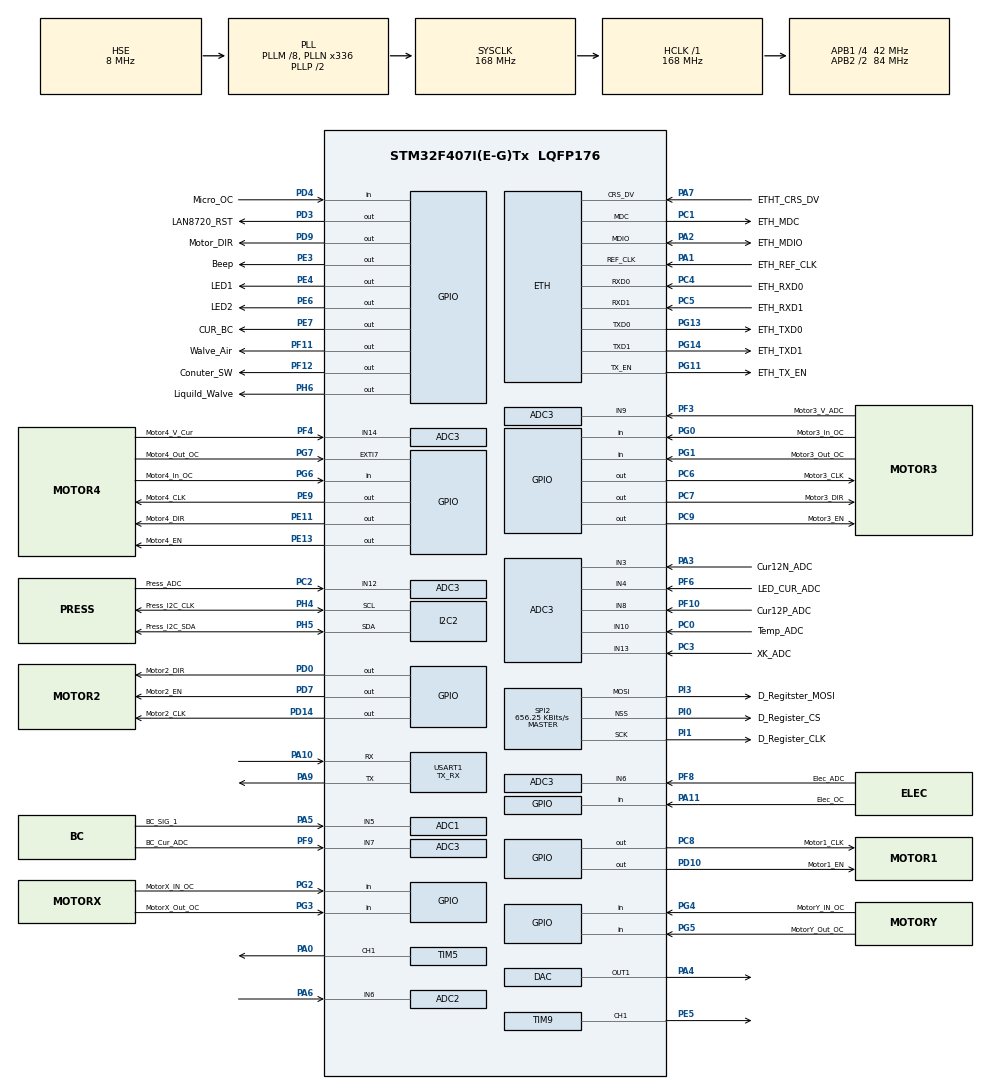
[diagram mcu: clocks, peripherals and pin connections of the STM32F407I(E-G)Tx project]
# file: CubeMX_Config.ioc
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ADC1.Channel-0\#ChannelRegularConversion=ADC_CHANNEL_5
ADC1.ContinuousConvMode=ENABLE
ADC1.DMAContinuousRequests=ENABLE
ADC1.InjNumberOfConversion=0
ADC1.NbrOfConversion=1
ADC1.NbrOfConversionFlag=1
ADC1.Rank-0\#ChannelRegularConversion=1
ADC1.SamplingTime-0\#ChannelRegularConversion=ADC_SAMPLETIME_3CYCLES
ADC1.master=1
ADC2.Channel-0\#ChannelRegularConversion=ADC_CHANNEL_6
ADC2.ContinuousConvMode=ENABLE
ADC2.DMAContinuousRequests=ENABLE
ADC2.NbrOfConversionFlag=1
ADC2.Rank-0\#ChannelRegularConversion=1
ADC2.SamplingTime-0\#ChannelRegularConversion=ADC_SAMPLETIME_3CYCLES
ADC2.ScanConvMode=ENABLE
ADC3.Channel-0\#ChannelRegularConversion=ADC_CHANNEL_13
ADC3.Channel-1\#ChannelRegularConversion=ADC_CHANNEL_7
ADC3.Channel-2\#ChannelRegularConversion=ADC_CHANNEL_6
ADC3.Channel-3\#ChannelRegularConversion=ADC_CHANNEL_3
ADC3.Channel-4\#ChannelRegularConversion=ADC_CHANNEL_8
ADC3.Channel-5\#ChannelRegularConversion=ADC_CHANNEL_9
ADC3.Channel-6\#ChannelRegularConversion=ADC_CHANNEL_14
ADC3.Channel-7\#ChannelRegularConversion=ADC_CHANNEL_12
ADC3.Channel-8\#ChannelRegularConversion=ADC_CHANNEL_4
ADC3.Channel-9\#ChannelRegularConversion=ADC_CHANNEL_10
ADC3.ContinuousConvMode=ENABLE
ADC3.NbrOfConversion=10
ADC3.NbrOfConversionFlag=1
ADC3.Rank-0\#ChannelRegularConversion=1
ADC3.Rank-1\#ChannelRegularConversion=2
ADC3.Rank-2\#ChannelRegularConversion=3
ADC3.Rank-3\#ChannelRegularConversion=4
ADC3.Rank-4\#ChannelRegularConversion=5
ADC3.Rank-5\#ChannelRegularConversion=6
ADC3.Rank-6\#ChannelRegularConversion=7
ADC3.Rank-7\#ChannelRegularConversion=8
ADC3.Rank-8\#ChannelRegularConversion=9
ADC3.Rank-9\#ChannelRegularConversion=10
ADC3.SamplingTime-0\#ChannelRegularConversion=ADC_SAMPLETIME_3CYCLES
ADC3.SamplingTime-1\#ChannelRegularConversion=ADC_SAMPLETIME_3CYCLES
ADC3.SamplingTime-2\#ChannelRegularConversion=ADC_SAMPLETIME_3CYCLES
ADC3.SamplingTime-3\#ChannelRegularConversion=ADC_SAMPLETIME_3CYCLES
ADC3.SamplingTime-4\#ChannelRegularConversion=ADC_SAMPLETIME_3CYCLES
ADC3.SamplingTime-5\#ChannelRegularConversion=ADC_SAMPLETIME_3CYCLES
ADC3.SamplingTime-6\#ChannelRegularConversion=ADC_SAMPLETIME_3CYCLES
ADC3.SamplingTime-7\#ChannelRegularConversion=ADC_SAMPLETIME_3CYCLES
ADC3.SamplingTime-8\#ChannelRegularConversion=ADC_SAMPLETIME_3CYCLES
ADC3.SamplingTime-9\#ChannelRegularConversion=ADC_SAMPLETIME_3CYCLES
ADC3.ScanConvMode=ENABLE
DAC.DAC_Trigger=DAC_TRIGGER_NONE
Dma.ADC1.0.Direction=DMA_PERIPH_TO_MEMORY
Dma.ADC1.0.FIFOMode=DMA_FIFOMODE_DISABLE
Dma.ADC1.0.Instance=DMA2_Stream0
Dma.ADC1.0.MemDataAlignment=DMA_MDATAALIGN_HALFWORD
Dma.ADC1.0.MemInc=DMA_MINC_ENABLE
Dma.ADC1.0.Mode=DMA_NORMAL
Dma.ADC1.0.PeriphDataAlignment=DMA_PDATAALIGN_HALFWORD
Dma.ADC1.0.PeriphInc=DMA_PINC_DISABLE
Dma.ADC1.0.Priority=DMA_PRIORITY_HIGH
Dma.ADC2.1.Direction=DMA_PERIPH_TO_MEMORY
Dma.ADC2.1.FIFOMode=DMA_FIFOMODE_DISABLE
Dma.ADC2.1.Instance=DMA2_Stream3
Dma.ADC2.1.MemDataAlignment=DMA_MDATAALIGN_HALFWORD
Dma.ADC2.1.MemInc=DMA_MINC_ENABLE
Dma.ADC2.1.Mode=DMA_NORMAL
Dma.ADC2.1.PeriphDataAlignment=DMA_PDATAALIGN_HALFWORD
Dma.ADC2.1.PeriphInc=DMA_PINC_DISABLE
Dma.ADC2.1.Priority=DMA_PRIORITY_HIGH
Dma.ADC3.2.Direction=DMA_PERIPH_TO_MEMORY
Dma.ADC3.2.FIFOMode=DMA_FIFOMODE_DISABLE
Dma.ADC3.2.Instance=DMA2_Stream1
Dma.ADC3.2.MemDataAlignment=DMA_MDATAALIGN_HALFWORD
Dma.ADC3.2.MemInc=DMA_MINC_ENABLE
Dma.ADC3.2.Mode=DMA_NORMAL
Dma.ADC3.2.PeriphDataAlignment=DMA_PDATAALIGN_HALFWORD
Dma.ADC3.2.PeriphInc=DMA_PINC_DISABLE
Dma.ADC3.2.Priority=DMA_PRIORITY_LOW
Dma.Request0=ADC1
Dma.Request1=ADC2
Dma.Request2=ADC3
ETH.AutoNegotiation=ETH_AUTONEGOTIATION_DISABLE
ETH.MediaInterface=ETH_MEDIA_INTERFACE_RMII
ETH.PHY_Name_RMII=LAN8742A_PHY_ADDRESS
FREERTOS.Tasks01=defaultTask,24,128,StartDefaultTask,Default,NULL,Dynamic,NULL,NULL
LWIP.CHECKSUM_BY_HARDWARE=1
LWIP.GATEWAY_ADDRESS=192.168.001.001
LWIP.IP_ADDRESS=192.168.001.010
LWIP.LWIP_DHCP=0
LWIP.NETMASK_ADDRESS=255.255.255.255
LWIP.Version=v2.1.2_Cube
Mcu.Family=STM32F4
Mcu.Name=STM32F407I(E-G)Tx
Mcu.Package=LQFP176
NVIC.ADC_IRQn=true\:5\:0\:false\:true\:true\:1\:true\:true\:true
NVIC.DMA2_Stream0_IRQn=true\:5\:0\:false\:true\:true\:7\:true\:false\:true
NVIC.DMA2_Stream1_IRQn=true\:5\:0\:false\:true\:true\:8\:true\:false\:true
NVIC.DMA2_Stream3_IRQn=true\:5\:0\:false\:true\:true\:9\:true\:false\:true
NVIC.ETH_IRQn=true\:5\:0\:true\:true\:true\:10\:true\:true\:true
NVIC.EXTI9_5_IRQn=true\:5\:0\:false\:true\:true\:2\:true\:true\:true
NVIC.PriorityGroup=NVIC_PRIORITYGROUP_4
NVIC.TIM1_UP_TIM10_IRQn=true\:5\:0\:false\:true\:true\:3\:true\:false\:true
NVIC.TIM2_IRQn=true\:5\:0\:false\:true\:true\:4\:true\:true\:true
NVIC.TIM8_UP_TIM13_IRQn=true\:5\:0\:false\:true\:true\:6\:true\:true\:true
NVIC.USART1_IRQn=true\:5\:0\:false\:true\:true\:5\:true\:true\:true
PA0-WKUP.Signal=S_TIM5_CH1
PA1.GPIO_Label=ETH_REF_CLK
PA1.Mode=RMII
PA1.Signal=ETH_REF_CLK
PA10.Mode=Asynchronous
PA10.Signal=USART1_RX
PA11.GPIO_Label=Elec_OC
PA11.Signal=GPIO_Input
PA13.Mode=Serial_Wire
PA13.Signal=SYS_JTMS-SWDIO
PA14.Mode=Serial_Wire
PA14.Signal=SYS_JTCK-SWCLK
PA2.GPIO_Label=ETH_MDIO
PA2.Mode=RMII
PA2.Signal=ETH_MDIO
PA3.GPIO_Label=Cur12N_ADC
PA3.Signal=ADCx_IN3
PA4.Signal=COMP_DAC1_group
PA5.GPIO_Label=BC_SIG_1
PA5.Signal=ADCx_IN5
PA6.Signal=ADCx_IN6
PA7.GPIO_Label=ETHT_CRS_DV
PA7.Mode=RMII
PA7.Signal=ETH_CRS_DV
PA9.Mode=Asynchronous
PA9.Signal=USART1_TX
PC0.GPIO_Label=Temp_ADC
PC0.Signal=ADCx_IN10
PC1.GPIO_Label=ETH_MDC
PC1.Mode=RMII
PC1.Signal=ETH_MDC
PC2.GPIO_Label=Press_ADC
PC2.Signal=ADCx_IN12
PC3.GPIO_Label=XK_ADC
PC3.Signal=ADCx_IN13
PC4.GPIO_Label=ETH_RXD0
PC4.Mode=RMII
PC4.Signal=ETH_RXD0
PC5.GPIO_Label=ETH_RXD1
PC5.Mode=RMII
PC5.Signal=ETH_RXD1
PC6.GPIO_Label=Motor3_CLK
PC6.GPIO_Speed=GPIO_SPEED_FREQ_HIGH
PC6.Signal=GPIO_Output
PC7.GPIO_Label=Motor3_DIR
PC7.Signal=GPIO_Output
PC8.GPIO_Label=Motor1_CLK
PC8.GPIO_Speed=GPIO_SPEED_FREQ_HIGH
PC8.Signal=GPIO_Output
PC9.GPIO_Label=Motor3_EN
PC9.Signal=GPIO_Output
PD0.GPIO_Label=Motor2_DIR
PD0.Signal=GPIO_Output
PD10.GPIO_Label=Motor1_EN
PD10.Signal=GPIO_Output
PD14.GPIO_Label=Motor2_CLK
PD14.GPIO_Speed=GPIO_SPEED_FREQ_HIGH
PD14.Signal=GPIO_Output
PD3.GPIO_Label=LAN8720_RST
PD3.Signal=GPIO_Output
PD4.GPIO_Label=Micro_OC
PD4.Signal=GPIO_Input
PD7.GPIO_Label=Motor2_EN
PD7.Signal=GPIO_Output
PD9.GPIO_Label=Motor_DIR
PD9.Signal=GPIO_Output
PE11.GPIO_Label=Motor4_DIR
PE11.Signal=GPIO_Output
PE13.GPIO_Label=Motor4_EN
PE13.Signal=GPIO_Output
PE3.GPIO_Label=Beep
PE3.Signal=GPIO_Output
PE4.GPIO_Label=LED1
PE4.Signal=GPIO_Output
PE5.Signal=S_TIM9_CH1
PE6.GPIO_Label=LED2
PE6.Signal=GPIO_Output
PE7.GPIO_Label=CUR_BC
PE7.Signal=GPIO_Output
PE9.GPIO_Label=Motor4_CLK
PE9.GPIO_Speed=GPIO_SPEED_FREQ_HIGH
PE9.Signal=GPIO_Output
PF10.GPIO_Label=Cur12P_ADC
PF10.Mode=IN8
PF10.Signal=ADC3_IN8
PF11.GPIO_Label=Walve_Air
PF11.Signal=GPIO_Output
PF12.GPIO_Label=Conuter_SW
PF12.Signal=GPIO_Output
PF3.GPIO_Label=Motor3_V_ADC
PF3.Mode=IN9
PF3.Signal=ADC3_IN9
PF4.GPIO_Label=Motor4_V_Cur
PF4.Mode=IN14
PF4.Signal=ADC3_IN14
PF6.GPIO_Label=LED_CUR_ADC
PF6.Mode=IN4
PF6.Signal=ADC3_IN4
PF8.GPIO_Label=Elec_ADC
PF8.Mode=IN6
PF8.Signal=ADC3_IN6
PF9.GPIO_Label=BC_Cur_ADC
PF9.Mode=IN7
PF9.Signal=ADC3_IN7
PG0.GPIO_Label=Motor3_In_OC
PG0.Signal=GPIO_Input
PG1.GPIO_Label=Motor3_Out_OC
PG1.Signal=GPIO_Input
PG11.GPIO_Label=ETH_TX_EN
PG11.Mode=RMII
PG11.Signal=ETH_TX_EN
PG13.GPIO_Label=ETH_TXD0
PG13.Mode=RMII
PG13.Signal=ETH_TXD0
PG14.GPIO_Label=ETH_TXD1
PG14.Mode=RMII
PG14.Signal=ETH_TXD1
PG2.GPIO_Label=MotorX_IN_OC
PG2.Signal=GPIO_Input
PG3.GPIO_Label=MotorX_Out_OC
PG3.Signal=GPIO_Input
PG4.GPIO_Label=MotorY_IN_OC
PG4.Signal=GPIO_Input
PG5.GPIO_Label=MotorY_Out_OC
PG5.Signal=GPIO_Input
PG6.GPIO_Label=Motor4_In_OC
PG6.Signal=GPIO_Input
PG7.GPIO_Label=Motor4_Out_OC
PG7.GPIO_ModeDefaultEXTI=GPIO_MODE_IT_RISING
PG7.Signal=GPXTI7
PH0-OSC_IN.Mode=HSE-External-Oscillator
PH0-OSC_IN.Signal=RCC_OSC_IN
PH1-OSC_OUT.Mode=HSE-External-Oscillator
PH1-OSC_OUT.Signal=RCC_OSC_OUT
PH4.GPIO_Label=Press_I2C_CLK
PH4.Mode=I2C
PH4.Signal=I2C2_SCL
PH5.GPIO_Label=Press_I2C_SDA
PH5.Mode=I2C
PH5.Signal=I2C2_SDA
PH6.GPIO_Label=Liquild_Walve
PH6.Signal=GPIO_Output
PI0.GPIO_Label=D_Register_CS
PI0.Mode=NSS_Signal_Hard_Output
PI0.Signal=SPI2_NSS
PI1.GPIO_Label=D_Register_CLK
PI1.Mode=TX_Only_Simplex_Unidirect_Master
PI1.Signal=SPI2_SCK
PI3.GPIO_Label=D_Regitster_MOSI
PI3.Mode=TX_Only_Simplex_Unidirect_Master
PI3.Signal=SPI2_MOSI
ProjectManager.HeapSize=0x200
ProjectManager.StackSize=0x400
ProjectManager.TargetToolchain=MDK-ARM V5
RCC.48MHZClocksFreq_Value=84000000
RCC.AHBFreq_Value=168000000
RCC.APB1CLKDivider=RCC_HCLK_DIV4
RCC.APB1Freq_Value=42000000
RCC.APB1TimFreq_Value=84000000
RCC.APB2CLKDivider=RCC_HCLK_DIV2
RCC.APB2Freq_Value=84000000
RCC.APB2TimFreq_Value=168000000
RCC.CortexFreq_Value=168000000
RCC.HCLKFreq_Value=168000000
RCC.HSE_VALUE=8000000
RCC.HSI_VALUE=16000000
RCC.LSE_VALUE=32768
RCC.PLLM=8
RCC.PLLN=336
RCC.PLLSourceVirtual=RCC_PLLSOURCE_HSE
RCC.SYSCLKFreq_VALUE=168000000
RCC.SYSCLKSource=RCC_SYSCLKSOURCE_PLLCLK
RCC.VCOOutputFreq_Value=336000000
SH.ADCx_IN10.0=ADC3_IN10,IN10
SH.ADCx_IN12.0=ADC3_IN12,IN12
SH.ADCx_IN13.0=ADC3_IN13,IN13
SH.ADCx_IN3.0=ADC3_IN3,IN3
SH.ADCx_IN5.0=ADC1_IN5,IN5
SH.ADCx_IN6.0=ADC2_IN6,IN6
SH.COMP_DAC1_group.0=DAC_OUT1,DAC_OUT1
SH.S_TIM5_CH1.0=TIM5_CH1,PWM Generation1 CH1
SH.S_TIM9_CH1.0=TIM9_CH1,PWM Generation1 CH1
SPI2.BaudRatePrescaler=SPI_BAUDRATEPRESCALER_64
SPI2.CalculateBaudRate=656.25 KBits/s
SPI2.DataSize=SPI_DATASIZE_16BIT
SPI2.Direction=SPI_DIRECTION_2LINES
SPI2.Mode=SPI_MODE_MASTER
SPI2.VirtualNSS=VM_NSSHARD
SPI2.VirtualType=VM_MASTER
TIM1.AutoReloadPreload=TIM_AUTORELOAD_PRELOAD_ENABLE
TIM1.Period=3000-1
TIM1.Prescaler=14-1
TIM2.AutoReloadPreload=TIM_AUTORELOAD_PRELOAD_ENABLE
TIM2.Period=6480-1
TIM2.Prescaler=256-1
TIM5.Channel-PWM\ Generation1\ CH1=TIM_CHANNEL_1
TIM5.OC1Preload_PWM=DISABLE
TIM5.OCPolarity_1=TIM_OCPOLARITY_LOW
TIM5.Prescaler=4199
TIM5.Pulse-PWM\ Generation1\ CH1=10000
TIM8.AutoReloadPreload=TIM_AUTORELOAD_PRELOAD_ENABLE
TIM8.Period=3000-1
TIM8.Prescaler=14-1
TIM9.AutoReloadPreload=TIM_AUTORELOAD_PRELOAD_ENABLE
TIM9.Channel-PWM\ Generation1\ CH1=TIM_CHANNEL_1
TIM9.OC1Preload_PWM=DISABLE
TIM9.OCPolarity_1=TIM_OCPOLARITY_LOW
TIM9.Period=24999
TIM9.Prescaler=83
TIM9.Pulse-PWM\ Generation1\ CH1=0
USART1.Mode=MODE_TX_RX
USART1.OverSampling=UART_OVERSAMPLING_8
USART1.VirtualMode=VM_ASYNC
VP_FREERTOS_VS_CMSIS_V2.Mode=CMSIS_V2
VP_LWIP_VS_Enabled.Mode=Enabled
VP_TIM1_VS_ClockSourceINT.Mode=Internal
VP_TIM2_VS_ClockSourceINT.Mode=Internal
VP_TIM8_VS_ClockSourceINT.Mode=Internal
board=custom

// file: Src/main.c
/* USER CODE BEGIN Header */
/**
  ******************************************************************************
  * @file           : main.c
  * @brief          : Main program body
  ******************************************************************************
  * @attention
  *
  * <h2><center>&copy; Copyright (c) 2020 STMicroelectronics.
  * All rights reserved.</center></h2>
  *
  * This software component is licensed by ST under Ultimate Liberty license
  * SLA0044, the "License"; You may not use this file except in compliance with
  * the License. You may obtain a copy of the License at:
  *                             www.st.com/SLA0044
  *
  ******************************************************************************
  */
/* USER CODE END Header */

#include "main.h"
#include "cmsis_os.h"
#include "lwip.h"

/* USER CODE BEGIN Includes */
#include "NetMsgProcess.h"
/* USER CODE END Includes */

ADC_HandleTypeDef hadc1;
ADC_HandleTypeDef hadc2;
ADC_HandleTypeDef hadc3;
DMA_HandleTypeDef hdma_adc1;
DMA_HandleTypeDef hdma_adc2;
DMA_HandleTypeDef hdma_adc3;

DAC_HandleTypeDef hdac;

I2C_HandleTypeDef hi2c2;

SPI_HandleTypeDef hspi2;

TIM_HandleTypeDef htim1;
TIM_HandleTypeDef htim2;
TIM_HandleTypeDef htim5;
TIM_HandleTypeDef htim8;
TIM_HandleTypeDef htim9;

UART_HandleTypeDef huart1;

/* Definitions for defaultTask */
osThreadId_t defaultTaskHandle;
const osThreadAttr_t defaultTask_attributes = {
  .name = "defaultTask",
  .priority = (osPriority_t) osPriorityNormal,
  .stack_size = 128 * 4
};

void SystemClock_Config(void);
static void MX_GPIO_Init(void);
static void MX_DMA_Init(void);
static void MX_ADC1_Init(void);
static void MX_ADC2_Init(void);
static void MX_ADC3_Init(void);
static void MX_DAC_Init(void);
static void MX_TIM5_Init(void);
static void MX_TIM9_Init(void);
static void MX_USART1_UART_Init(void);
static void MX_I2C2_Init(void);
static void MX_SPI2_Init(void);
static void MX_TIM1_Init(void);
static void MX_TIM2_Init(void);
static void MX_TIM8_Init(void);
void StartDefaultTask(void *argument);

static void MX_NVIC_Init(void);

int main(void)
{

  /* MCU Configuration--------------------------------------------------------*/

  /* Reset of all peripherals, Initializes the Flash interface and the Systick. */
  HAL_Init();

  /* Configure the system clock */
  SystemClock_Config();

  /* Initialize all configured peripherals */
  MX_GPIO_Init();
  MX_DMA_Init();
  MX_ADC1_Init();
  MX_ADC2_Init();
  MX_ADC3_Init();
  MX_DAC_Init();
  MX_TIM5_Init();
  MX_TIM9_Init();
  MX_USART1_UART_Init();
  MX_I2C2_Init();
  MX_SPI2_Init();
  MX_TIM1_Init();
  MX_TIM2_Init();
  MX_TIM8_Init();

  /* Initialize interrupts */
  MX_NVIC_Init();

  /* Init scheduler */
  osKernelInitialize();

  /* Create the thread(s) */
  /* creation of defaultTask */
  defaultTaskHandle = osThreadNew(StartDefaultTask, NULL, &defaultTask_attributes);

  /* Start scheduler */
  osKernelStart();

  /* We should never get here as control is now taken by the scheduler */
  /* Infinite loop */
  while (1)
  {

  }
}

void SystemClock_Config(void)
{
  RCC_OscInitTypeDef RCC_OscInitStruct = {0};
  RCC_ClkInitTypeDef RCC_ClkInitStruct = {0};

  /** Configure the main internal regulator output voltage
  */
  __HAL_RCC_PWR_CLK_ENABLE();
  __HAL_PWR_VOLTAGESCALING_CONFIG(PWR_REGULATOR_VOLTAGE_SCALE1);
  /** Initializes the CPU, AHB and APB busses clocks
  */
  RCC_OscInitStruct.OscillatorType = RCC_OSCILLATORTYPE_HSE;
  RCC_OscInitStruct.HSEState = RCC_HSE_ON;
  RCC_OscInitStruct.PLL.PLLState = RCC_PLL_ON;
  RCC_OscInitStruct.PLL.PLLSource = RCC_PLLSOURCE_HSE;
  RCC_OscInitStruct.PLL.PLLM = 8;
  RCC_OscInitStruct.PLL.PLLN = 336;
  RCC_OscInitStruct.PLL.PLLP = RCC_PLLP_DIV2;
  RCC_OscInitStruct.PLL.PLLQ = 4;
  if (HAL_RCC_OscConfig(&RCC_OscInitStruct) != HAL_OK)
  {
    Error_Handler();
  }
  /** Initializes the CPU, AHB and APB busses clocks
  */
  RCC_ClkInitStruct.ClockType = RCC_CLOCKTYPE_HCLK|RCC_CLOCKTYPE_SYSCLK
                              |RCC_CLOCKTYPE_PCLK1|RCC_CLOCKTYPE_PCLK2;
  RCC_ClkInitStruct.SYSCLKSource = RCC_SYSCLKSOURCE_PLLCLK;
  RCC_ClkInitStruct.AHBCLKDivider = RCC_SYSCLK_DIV1;
  RCC_ClkInitStruct.APB1CLKDivider = RCC_HCLK_DIV4;
  RCC_ClkInitStruct.APB2CLKDivider = RCC_HCLK_DIV2;

  if (HAL_RCC_ClockConfig(&RCC_ClkInitStruct, FLASH_LATENCY_5) != HAL_OK)
  {
    Error_Handler();
  }
}

/**
  * @brief NVIC Configuration.
  * @retval None
  */
static void MX_NVIC_Init(void)
{
  /* ADC_IRQn interrupt configuration */
  HAL_NVIC_SetPriority(ADC_IRQn, 5, 0);
  HAL_NVIC_EnableIRQ(ADC_IRQn);
  /* EXTI9_5_IRQn interrupt configuration */
  HAL_NVIC_SetPriority(EXTI9_5_IRQn, 5, 0);
  HAL_NVIC_EnableIRQ(EXTI9_5_IRQn);
  /* TIM1_UP_TIM10_IRQn interrupt configuration */
  HAL_NVIC_SetPriority(TIM1_UP_TIM10_IRQn, 5, 0);
  HAL_NVIC_EnableIRQ(TIM1_UP_TIM10_IRQn);
  /* TIM2_IRQn interrupt configuration */
  HAL_NVIC_SetPriority(TIM2_IRQn, 5, 0);
  HAL_NVIC_EnableIRQ(TIM2_IRQn);
  /* USART1_IRQn interrupt configuration */
  HAL_NVIC_SetPriority(USART1_IRQn, 5, 0);
  HAL_NVIC_EnableIRQ(USART1_IRQn);
  /* TIM8_UP_TIM13_IRQn interrupt configuration */
  HAL_NVIC_SetPriority(TIM8_UP_TIM13_IRQn, 5, 0);
  HAL_NVIC_EnableIRQ(TIM8_UP_TIM13_IRQn);
  /* DMA2_Stream0_IRQn interrupt configuration */
  HAL_NVIC_SetPriority(DMA2_Stream0_IRQn, 5, 0);
  HAL_NVIC_EnableIRQ(DMA2_Stream0_IRQn);
  /* DMA2_Stream1_IRQn interrupt configuration */
  HAL_NVIC_SetPriority(DMA2_Stream1_IRQn, 5, 0);
  HAL_NVIC_EnableIRQ(DMA2_Stream1_IRQn);
  /* DMA2_Stream3_IRQn interrupt configuration */
  HAL_NVIC_SetPriority(DMA2_Stream3_IRQn, 5, 0);
  HAL_NVIC_EnableIRQ(DMA2_Stream3_IRQn);
  /* ETH_IRQn interrupt configuration */
  HAL_NVIC_SetPriority(ETH_IRQn, 5, 0);
  HAL_NVIC_EnableIRQ(ETH_IRQn);
}

static void MX_ADC1_Init(void)
{

  ADC_ChannelConfTypeDef sConfig = {0};

  /** Configure the global features of the ADC (Clock, Resolution, Data Alignment and number of conversion)
  */
  hadc1.Instance = ADC1;
  hadc1.Init.ClockPrescaler = ADC_CLOCK_SYNC_PCLK_DIV4;
  hadc1.Init.Resolution = ADC_RESOLUTION_12B;
  hadc1.Init.ScanConvMode = DISABLE;
  hadc1.Init.ContinuousConvMode = ENABLE;
  hadc1.Init.DiscontinuousConvMode = DISABLE;
  hadc1.Init.ExternalTrigConvEdge = ADC_EXTERNALTRIGCONVEDGE_NONE;
  hadc1.Init.ExternalTrigConv = ADC_SOFTWARE_START;
  hadc1.Init.DataAlign = ADC_DATAALIGN_RIGHT;
  hadc1.Init.NbrOfConversion = 1;
  hadc1.Init.DMAContinuousRequests = ENABLE;
  hadc1.Init.EOCSelection = ADC_EOC_SINGLE_CONV;
  if (HAL_ADC_Init(&hadc1) != HAL_OK)
  {
    Error_Handler();
  }
  /** Configure for the selected ADC regular channel its corresponding rank in the sequencer and its sample time.
  */
  sConfig.Channel = ADC_CHANNEL_5;
  sConfig.Rank = 1;
  sConfig.SamplingTime = ADC_SAMPLETIME_3CYCLES;
  if (HAL_ADC_ConfigChannel(&hadc1, &sConfig) != HAL_OK)
  {
    Error_Handler();
  }

}

static void MX_ADC2_Init(void)
{

  ADC_ChannelConfTypeDef sConfig = {0};

  /** Configure the global features of the ADC (Clock, Resolution, Data Alignment and number of conversion)
  */
  hadc2.Instance = ADC2;
  hadc2.Init.ClockPrescaler = ADC_CLOCK_SYNC_PCLK_DIV4;
  hadc2.Init.Resolution = ADC_RESOLUTION_12B;
  hadc2.Init.ScanConvMode = ENABLE;
  hadc2.Init.ContinuousConvMode = ENABLE;
  hadc2.Init.DiscontinuousConvMode = DISABLE;
  hadc2.Init.ExternalTrigConvEdge = ADC_EXTERNALTRIGCONVEDGE_NONE;
  hadc2.Init.ExternalTrigConv = ADC_SOFTWARE_START;
  hadc2.Init.DataAlign = ADC_DATAALIGN_RIGHT;
  hadc2.Init.NbrOfConversion = 1;
  hadc2.Init.DMAContinuousRequests = ENABLE;
  hadc2.Init.EOCSelection = ADC_EOC_SINGLE_CONV;
  if (HAL_ADC_Init(&hadc2) != HAL_OK)
  {
    Error_Handler();
  }
  /** Configure for the selected ADC regular channel its corresponding rank in the sequencer and its sample time.
  */
  sConfig.Channel = ADC_CHANNEL_6;
  sConfig.Rank = 1;
  sConfig.SamplingTime = ADC_SAMPLETIME_3CYCLES;
  if (HAL_ADC_ConfigChannel(&hadc2, &sConfig) != HAL_OK)
  {
    Error_Handler();
  }

}

static void MX_ADC3_Init(void)
{

  ADC_ChannelConfTypeDef sConfig = {0};

  /** Configure the global features of the ADC (Clock, Resolution, Data Alignment and number of conversion)
  */
  hadc3.Instance = ADC3;
  hadc3.Init.ClockPrescaler = ADC_CLOCK_SYNC_PCLK_DIV4;
  hadc3.Init.Resolution = ADC_RESOLUTION_12B;
  hadc3.Init.ScanConvMode = ENABLE;
  hadc3.Init.ContinuousConvMode = ENABLE;
  hadc3.Init.DiscontinuousConvMode = DISABLE;
  hadc3.Init.ExternalTrigConvEdge = ADC_EXTERNALTRIGCONVEDGE_NONE;
  hadc3.Init.ExternalTrigConv = ADC_SOFTWARE_START;
  hadc3.Init.DataAlign = ADC_DATAALIGN_RIGHT;
  hadc3.Init.NbrOfConversion = 10;
  hadc3.Init.DMAContinuousRequests = DISABLE;
  hadc3.Init.EOCSelection = ADC_EOC_SINGLE_CONV;
  if (HAL_ADC_Init(&hadc3) != HAL_OK)
  {
    Error_Handler();
  }
  /** Configure for the selected ADC regular channel its corresponding rank in the sequencer and its sample time.
  */
  sConfig.Channel = ADC_CHANNEL_13;
  sConfig.Rank = 1;
  sConfig.SamplingTime = ADC_SAMPLETIME_3CYCLES;
  if (HAL_ADC_ConfigChannel(&hadc3, &sConfig) != HAL_OK)
  {
    Error_Handler();
  }
  /** Configure for the selected ADC regular channel its corresponding rank in the sequencer and its sample time.
  */
  sConfig.Channel = ADC_CHANNEL_7;
  sConfig.Rank = 2;
  if (HAL_ADC_ConfigChannel(&hadc3, &sConfig) != HAL_OK)
  {
    Error_Handler();
  }
  /** Configure for the selected ADC regular channel its corresponding rank in the sequencer and its sample time.
  */
  sConfig.Channel = ADC_CHANNEL_6;
  sConfig.Rank = 3;
  if (HAL_ADC_ConfigChannel(&hadc3, &sConfig) != HAL_OK)
  {
    Error_Handler();
  }
  /** Configure for the selected ADC regular channel its corresponding rank in the sequencer and its sample time.
  */
  sConfig.Channel = ADC_CHANNEL_3;
  sConfig.Rank = 4;
  if (HAL_ADC_ConfigChannel(&hadc3, &sConfig) != HAL_OK)
  {
    Error_Handler();
  }
  /** Configure for the selected ADC regular channel its corresponding rank in the sequencer and its sample time.
  */
  sConfig.Channel = ADC_CHANNEL_8;
  sConfig.Rank = 5;
  if (HAL_ADC_ConfigChannel(&hadc3, &sConfig) != HAL_OK)
  {
    Error_Handler();
  }
  /** Configure for the selected ADC regular channel its corresponding rank in the sequencer and its sample time.
  */
  sConfig.Channel = ADC_CHANNEL_9;
  sConfig.Rank = 6;
  if (HAL_ADC_ConfigChannel(&hadc3, &sConfig) != HAL_OK)
  {
    Error_Handler();
  }
  /** Configure for the selected ADC regular channel its corresponding rank in the sequencer and its sample time.
  */
  sConfig.Channel = ADC_CHANNEL_14;
  sConfig.Rank = 7;
  if (HAL_ADC_ConfigChannel(&hadc3, &sConfig) != HAL_OK)
  {
    Error_Handler();
  }
  /** Configure for the selected ADC regular channel its corresponding rank in the sequencer and its sample time.
  */
  sConfig.Channel = ADC_CHANNEL_12;
  sConfig.Rank = 8;
  if (HAL_ADC_ConfigChannel(&hadc3, &sConfig) != HAL_OK)
  {
    Error_Handler();
  }
  /** Configure for the selected ADC regular channel its corresponding rank in the sequencer and its sample time.
  */
  sConfig.Channel = ADC_CHANNEL_4;
  sConfig.Rank = 9;
  if (HAL_ADC_ConfigChannel(&hadc3, &sConfig) != HAL_OK)
  {
    Error_Handler();
  }
  /** Configure for the selected ADC regular channel its corresponding rank in the sequencer and its sample time.
  */
  sConfig.Channel = ADC_CHANNEL_10;
  sConfig.Rank = 10;
  if (HAL_ADC_ConfigChannel(&hadc3, &sConfig) != HAL_OK)
  {
    Error_Handler();
  }

}

static void MX_DAC_Init(void)
{

  DAC_ChannelConfTypeDef sConfig = {0};

  /** DAC Initialization
  */
  hdac.Instance = DAC;
  if (HAL_DAC_Init(&hdac) != HAL_OK)
  {
    Error_Handler();
  }
  /** DAC channel OUT1 config
  */
  sConfig.DAC_Trigger = DAC_TRIGGER_NONE;
  sConfig.DAC_OutputBuffer = DAC_OUTPUTBUFFER_ENABLE;
  if (HAL_DAC_ConfigChannel(&hdac, &sConfig, DAC_CHANNEL_1) != HAL_OK)
  {
    Error_Handler();
  }

}

static void MX_I2C2_Init(void)
{

  hi2c2.Instance = I2C2;
  hi2c2.Init.ClockSpeed = 100000;
  hi2c2.Init.DutyCycle = I2C_DUTYCYCLE_2;
  hi2c2.Init.OwnAddress1 = 0;
  hi2c2.Init.AddressingMode = I2C_ADDRESSINGMODE_7BIT;
  hi2c2.Init.DualAddressMode = I2C_DUALADDRESS_DISABLE;
  hi2c2.Init.OwnAddress2 = 0;
  hi2c2.Init.GeneralCallMode = I2C_GENERALCALL_DISABLE;
  hi2c2.Init.NoStretchMode = I2C_NOSTRETCH_DISABLE;
  if (HAL_I2C_Init(&hi2c2) != HAL_OK)
  {
    Error_Handler();
  }

}

static void MX_SPI2_Init(void)
{

  /* SPI2 parameter configuration*/
  hspi2.Instance = SPI2;
  hspi2.Init.Mode = SPI_MODE_MASTER;
  hspi2.Init.Direction = SPI_DIRECTION_2LINES;
  hspi2.Init.DataSize = SPI_DATASIZE_16BIT;
  hspi2.Init.CLKPolarity = SPI_POLARITY_LOW;
  hspi2.Init.CLKPhase = SPI_PHASE_1EDGE;
  hspi2.Init.NSS = SPI_NSS_HARD_OUTPUT;
  hspi2.Init.BaudRatePrescaler = SPI_BAUDRATEPRESCALER_64;
  hspi2.Init.FirstBit = SPI_FIRSTBIT_MSB;
  hspi2.Init.TIMode = SPI_TIMODE_DISABLE;
  hspi2.Init.CRCCalculation = SPI_CRCCALCULATION_DISABLE;
  hspi2.Init.CRCPolynomial = 10;
  if (HAL_SPI_Init(&hspi2) != HAL_OK)
  {
    Error_Handler();
  }

}

static void MX_TIM1_Init(void)
{

  TIM_ClockConfigTypeDef sClockSourceConfig = {0};
  TIM_MasterConfigTypeDef sMasterConfig = {0};

  htim1.Instance = TIM1;
  htim1.Init.Prescaler = 14-1;
  htim1.Init.CounterMode = TIM_COUNTERMODE_UP;
  htim1.Init.Period = 3000-1;
  htim1.Init.ClockDivision = TIM_CLOCKDIVISION_DIV1;
  htim1.Init.RepetitionCounter = 0;
  htim1.Init.AutoReloadPreload = TIM_AUTORELOAD_PRELOAD_ENABLE;
  if (HAL_TIM_Base_Init(&htim1) != HAL_OK)
  {
    Error_Handler();
  }
  sClockSourceConfig.ClockSource = TIM_CLOCKSOURCE_INTERNAL;
  if (HAL_TIM_ConfigClockSource(&htim1, &sClockSourceConfig) != HAL_OK)
  {
    Error_Handler();
  }
  sMasterConfig.MasterOutputTrigger = TIM_TRGO_RESET;
  sMasterConfig.MasterSlaveMode = TIM_MASTERSLAVEMODE_DISABLE;
  if (HAL_TIMEx_MasterConfigSynchronization(&htim1, &sMasterConfig) != HAL_OK)
  {
    Error_Handler();
  }

}

static void MX_TIM2_Init(void)
{

  TIM_ClockConfigTypeDef sClockSourceConfig = {0};
  TIM_MasterConfigTypeDef sMasterConfig = {0};

  htim2.Instance = TIM2;
  htim2.Init.Prescaler = 256-1;
  htim2.Init.CounterMode = TIM_COUNTERMODE_UP;
  htim2.Init.Period = 6480-1;
  htim2.Init.ClockDivision = TIM_CLOCKDIVISION_DIV1;
  htim2.Init.AutoReloadPreload = TIM_AUTORELOAD_PRELOAD_ENABLE;
  if (HAL_TIM_Base_Init(&htim2) != HAL_OK)
  {
    Error_Handler();
  }
  sClockSourceConfig.ClockSource = TIM_CLOCKSOURCE_INTERNAL;
  if (HAL_TIM_ConfigClockSource(&htim2, &sClockSourceConfig) != HAL_OK)
  {
    Error_Handler();
  }
  sMasterConfig.MasterOutputTrigger = TIM_TRGO_RESET;
  sMasterConfig.MasterSlaveMode = TIM_MASTERSLAVEMODE_DISABLE;
  if (HAL_TIMEx_MasterConfigSynchronization(&htim2, &sMasterConfig) != HAL_OK)
  {
    Error_Handler();
  }

}

static void MX_TIM5_Init(void)
{

  TIM_MasterConfigTypeDef sMasterConfig = {0};
  TIM_OC_InitTypeDef sConfigOC = {0};

  htim5.Instance = TIM5;
  htim5.Init.Prescaler = 4199;
  htim5.Init.CounterMode = TIM_COUNTERMODE_UP;
  htim5.Init.Period = 0;
  htim5.Init.ClockDivision = TIM_CLOCKDIVISION_DIV1;
  htim5.Init.AutoReloadPreload = TIM_AUTORELOAD_PRELOAD_DISABLE;
  if (HAL_TIM_PWM_Init(&htim5) != HAL_OK)
  {
    Error_Handler();
  }
  sMasterConfig.MasterOutputTrigger = TIM_TRGO_RESET;
  sMasterConfig.MasterSlaveMode = TIM_MASTERSLAVEMODE_DISABLE;
  if (HAL_TIMEx_MasterConfigSynchronization(&htim5, &sMasterConfig) != HAL_OK)
  {
    Error_Handler();
  }
  sConfigOC.OCMode = TIM_OCMODE_PWM1;
  sConfigOC.Pulse = 10000;
  sConfigOC.OCPolarity = TIM_OCPOLARITY_LOW;
  sConfigOC.OCFastMode = TIM_OCFAST_DISABLE;
  if (HAL_TIM_PWM_ConfigChannel(&htim5, &sConfigOC, TIM_CHANNEL_1) != HAL_OK)
  {
    Error_Handler();
  }
  __HAL_TIM_DISABLE_OCxPRELOAD(&htim5, TIM_CHANNEL_1);
  HAL_TIM_MspPostInit(&htim5);

}

static void MX_TIM8_Init(void)
{

  TIM_ClockConfigTypeDef sClockSourceConfig = {0};
  TIM_MasterConfigTypeDef sMasterConfig = {0};

  htim8.Instance = TIM8;
  htim8.Init.Prescaler = 14-1;
  htim8.Init.CounterMode = TIM_COUNTERMODE_UP;
  htim8.Init.Period = 3000-1;
  htim8.Init.ClockDivision = TIM_CLOCKDIVISION_DIV1;
  htim8.Init.RepetitionCounter = 0;
  htim8.Init.AutoReloadPreload = TIM_AUTORELOAD_PRELOAD_ENABLE;
  if (HAL_TIM_Base_Init(&htim8) != HAL_OK)
  {
    Error_Handler();
  }
  sClockSourceConfig.ClockSource = TIM_CLOCKSOURCE_INTERNAL;
  if (HAL_TIM_ConfigClockSource(&htim8, &sClockSourceConfig) != HAL_OK)
  {
    Error_Handler();
  }
  sMasterConfig.MasterOutputTrigger = TIM_TRGO_RESET;
  sMasterConfig.MasterSlaveMode = TIM_MASTERSLAVEMODE_DISABLE;
  if (HAL_TIMEx_MasterConfigSynchronization(&htim8, &sMasterConfig) != HAL_OK)
  {
    Error_Handler();
  }

}

static void MX_TIM9_Init(void)
{

  TIM_OC_InitTypeDef sConfigOC = {0};

  htim9.Instance = TIM9;
  htim9.Init.Prescaler = 83;
  htim9.Init.CounterMode = TIM_COUNTERMODE_UP;
  htim9.Init.Period = 24999;
  htim9.Init.ClockDivision = TIM_CLOCKDIVISION_DIV1;
  htim9.Init.AutoReloadPreload = TIM_AUTORELOAD_PRELOAD_ENABLE;
  if (HAL_TIM_PWM_Init(&htim9) != HAL_OK)
  {
    Error_Handler();
  }
  sConfigOC.OCMode = TIM_OCMODE_PWM1;
  sConfigOC.Pulse = 0;
  sConfigOC.OCPolarity = TIM_OCPOLARITY_LOW;
  sConfigOC.OCFastMode = TIM_OCFAST_DISABLE;
  if (HAL_TIM_PWM_ConfigChannel(&htim9, &sConfigOC, TIM_CHANNEL_1) != HAL_OK)
  {
    Error_Handler();
  }
  __HAL_TIM_DISABLE_OCxPRELOAD(&htim9, TIM_CHANNEL_1);
  HAL_TIM_MspPostInit(&htim9);

}

static void MX_USART1_UART_Init(void)
{

  huart1.Instance = USART1;
  huart1.Init.BaudRate = 115200;
  huart1.Init.WordLength = UART_WORDLENGTH_8B;
  huart1.Init.StopBits = UART_STOPBITS_1;
  huart1.Init.Parity = UART_PARITY_NONE;
  huart1.Init.Mode = UART_MODE_TX_RX;
  huart1.Init.HwFlowCtl = UART_HWCONTROL_NONE;
  huart1.Init.OverSampling = UART_OVERSAMPLING_8;
  if (HAL_UART_Init(&huart1) != HAL_OK)
  {
    Error_Handler();
  }

}

static void MX_DMA_Init(void)
{

  /* DMA controller clock enable */
  __HAL_RCC_DMA2_CLK_ENABLE();

}

static void MX_GPIO_Init(void)
{
  GPIO_InitTypeDef GPIO_InitStruct = {0};

  /* GPIO Ports Clock Enable */
  __HAL_RCC_GPIOE_CLK_ENABLE();
  __HAL_RCC_GPIOF_CLK_ENABLE();
  __HAL_RCC_GPIOH_CLK_ENABLE();
  __HAL_RCC_GPIOC_CLK_ENABLE();
  __HAL_RCC_GPIOA_CLK_ENABLE();
  __HAL_RCC_GPIOG_CLK_ENABLE();
  __HAL_RCC_GPIOD_CLK_ENABLE();
  __HAL_RCC_GPIOI_CLK_ENABLE();

  /*Configure GPIO pin Output Level */
  HAL_GPIO_WritePin(GPIOE, Beep_Pin|LED1_Pin|LED2_Pin|CUR_BC_Pin
                          |Motor4_CLK_Pin|Motor4_DIR_Pin|Motor4_EN_Pin, GPIO_PIN_RESET);

  /*Configure GPIO pin Output Level */
  HAL_GPIO_WritePin(GPIOF, Walve_Air_Pin|Conuter_SW_Pin, GPIO_PIN_RESET);

  /*Configure GPIO pin Output Level */
  HAL_GPIO_WritePin(Liquild_Walve_GPIO_Port, Liquild_Walve_Pin, GPIO_PIN_RESET);

  /*Configure GPIO pin Output Level */
  HAL_GPIO_WritePin(GPIOD, Motor_DIR_Pin|Motor1_EN_Pin|Motor2_CLK_Pin|Motor2_DIR_Pin
                          |LAN8720_RST_Pin|Motor2_EN_Pin, GPIO_PIN_RESET);

  /*Configure GPIO pin Output Level */
  HAL_GPIO_WritePin(GPIOC, Motor3_CLK_Pin|Motor3_DIR_Pin|Motor1_CLK_Pin|Motor3_EN_Pin, GPIO_PIN_RESET);

  /*Configure GPIO pins : Beep_Pin LED1_Pin LED2_Pin CUR_BC_Pin
                           Motor4_DIR_Pin Motor4_EN_Pin */
  GPIO_InitStruct.Pin = Beep_Pin|LED1_Pin|LED2_Pin|CUR_BC_Pin
                          |Motor4_DIR_Pin|Motor4_EN_Pin;
  GPIO_InitStruct.Mode = GPIO_MODE_OUTPUT_PP;
  GPIO_InitStruct.Pull = GPIO_NOPULL;
  GPIO_InitStruct.Speed = GPIO_SPEED_FREQ_LOW;
  HAL_GPIO_Init(GPIOE, &GPIO_InitStruct);

  /*Configure GPIO pins : Walve_Air_Pin Conuter_SW_Pin */
  GPIO_InitStruct.Pin = Walve_Air_Pin|Conuter_SW_Pin;
  GPIO_InitStruct.Mode = GPIO_MODE_OUTPUT_PP;
  GPIO_InitStruct.Pull = GPIO_NOPULL;
  GPIO_InitStruct.Speed = GPIO_SPEED_FREQ_LOW;
  HAL_GPIO_Init(GPIOF, &GPIO_InitStruct);

  /*Configure GPIO pins : Motor3_In_OC_Pin Motor3_Out_OC_Pin MotorX_IN_OC_Pin MotorX_Out_OC_Pin
                           MotorY_IN_OC_Pin MotorY_Out_OC_Pin Motor4_In_OC_Pin */
  GPIO_InitStruct.Pin = Motor3_In_OC_Pin|Motor3_Out_OC_Pin|MotorX_IN_OC_Pin|MotorX_Out_OC_Pin
                          |MotorY_IN_OC_Pin|MotorY_Out_OC_Pin|Motor4_In_OC_Pin;
  GPIO_InitStruct.Mode = GPIO_MODE_INPUT;
  GPIO_InitStruct.Pull = GPIO_NOPULL;
  HAL_GPIO_Init(GPIOG, &GPIO_InitStruct);

  /*Configure GPIO pin : Motor4_CLK_Pin */
  GPIO_InitStruct.Pin = Motor4_CLK_Pin;
  GPIO_InitStruct.Mode = GPIO_MODE_OUTPUT_PP;
  GPIO_InitStruct.Pull = GPIO_NOPULL;
  GPIO_InitStruct.Speed = GPIO_SPEED_FREQ_HIGH;
  HAL_GPIO_Init(Motor4_CLK_GPIO_Port, &GPIO_InitStruct);

  /*Configure GPIO pin : Liquild_Walve_Pin */
  GPIO_InitStruct.Pin = Liquild_Walve_Pin;
  GPIO_InitStruct.Mode = GPIO_MODE_OUTPUT_PP;
  GPIO_InitStruct.Pull = GPIO_NOPULL;
  GPIO_InitStruct.Speed = GPIO_SPEED_FREQ_LOW;
  HAL_GPIO_Init(Liquild_Walve_GPIO_Port, &GPIO_InitStruct);

  /*Configure GPIO pins : Motor_DIR_Pin Motor1_EN_Pin Motor2_DIR_Pin LAN8720_RST_Pin
                           Motor2_EN_Pin */
  GPIO_InitStruct.Pin = Motor_DIR_Pin|Motor1_EN_Pin|Motor2_DIR_Pin|LAN8720_RST_Pin
                          |Motor2_EN_Pin;
  GPIO_InitStruct.Mode = GPIO_MODE_OUTPUT_PP;
  GPIO_InitStruct.Pull = GPIO_NOPULL;
  GPIO_InitStruct.Speed = GPIO_SPEED_FREQ_LOW;
  HAL_GPIO_Init(GPIOD, &GPIO_InitStruct);

  /*Configure GPIO pin : Motor2_CLK_Pin */
  GPIO_InitStruct.Pin = Motor2_CLK_Pin;
  GPIO_InitStruct.Mode = GPIO_MODE_OUTPUT_PP;
  GPIO_InitStruct.Pull = GPIO_NOPULL;
  GPIO_InitStruct.Speed = GPIO_SPEED_FREQ_HIGH;
  HAL_GPIO_Init(Motor2_CLK_GPIO_Port, &GPIO_InitStruct);

  /*Configure GPIO pin : Motor4_Out_OC_Pin */
  GPIO_InitStruct.Pin = Motor4_Out_OC_Pin;
  GPIO_InitStruct.Mode = GPIO_MODE_IT_RISING;
  GPIO_InitStruct.Pull = GPIO_NOPULL;
  HAL_GPIO_Init(Motor4_Out_OC_GPIO_Port, &GPIO_InitStruct);

  /*Configure GPIO pins : Motor3_CLK_Pin Motor1_CLK_Pin */
  GPIO_InitStruct.Pin = Motor3_CLK_Pin|Motor1_CLK_Pin;
  GPIO_InitStruct.Mode = GPIO_MODE_OUTPUT_PP;
  GPIO_InitStruct.Pull = GPIO_NOPULL;
  GPIO_InitStruct.Speed = GPIO_SPEED_FREQ_HIGH;
  HAL_GPIO_Init(GPIOC, &GPIO_InitStruct);

  /*Configure GPIO pins : Motor3_DIR_Pin Motor3_EN_Pin */
  GPIO_InitStruct.Pin = Motor3_DIR_Pin|Motor3_EN_Pin;
  GPIO_InitStruct.Mode = GPIO_MODE_OUTPUT_PP;
  GPIO_InitStruct.Pull = GPIO_NOPULL;
  GPIO_InitStruct.Speed = GPIO_SPEED_FREQ_LOW;
  HAL_GPIO_Init(GPIOC, &GPIO_InitStruct);

  /*Configure GPIO pin : Elec_OC_Pin */
  GPIO_InitStruct.Pin = Elec_OC_Pin;
  GPIO_InitStruct.Mode = GPIO_MODE_INPUT;
  GPIO_InitStruct.Pull = GPIO_NOPULL;
  HAL_GPIO_Init(Elec_OC_GPIO_Port, &GPIO_InitStruct);

  /*Configure GPIO pin : Micro_OC_Pin */
  GPIO_InitStruct.Pin = Micro_OC_Pin;
  GPIO_InitStruct.Mode = GPIO_MODE_INPUT;
  GPIO_InitStruct.Pull = GPIO_NOPULL;
  HAL_GPIO_Init(Micro_OC_GPIO_Port, &GPIO_InitStruct);

}

void StartDefaultTask(void *argument)
{
  /* init code for LWIP */
  MX_LWIP_Init();
  /* USER CODE BEGIN 5 */

//	osThreadId_t defaultTaskHandle;
//	const osThreadAttr_t defaultTask_attributes = {
//	  .name = "defaultTask",
//	  .priority = (osPriority_t) osPriorityNormal,
//	  .stack_size = 128 * 4
//	};
//	defaultTaskHandle = osThreadNew(StartDefaultTask, NULL, &defaultTask_attributes);

	Net_Msg_Handler();

  /* USER CODE END 5 */
}

void Error_Handler(void)
{
}

/************************ (C) COPYRIGHT STMicroelectronics *****END OF FILE****/
